# MK50D10 register map
Vendor: Freescale Semiconductor, Inc.; Series: Kinetis_K; File version: 1.6
CPU: CM4 r0p1, little endian, no MPU, no FPU, VTOR, 4 interrupt priority bits
Registers are 8-bit, read-write, reset 0x0 unless marked. A register's access mark holds for its fields unless they carry their own. Offsets are from the block's base; [hi:lo] are bit positions; {n}, {i} and the like mark numbered series; 'fields as' and 'values as' point back to an identical list.

## MPU — Memory protection unit
Base 0x4000D000; register names take the prefix MPU_
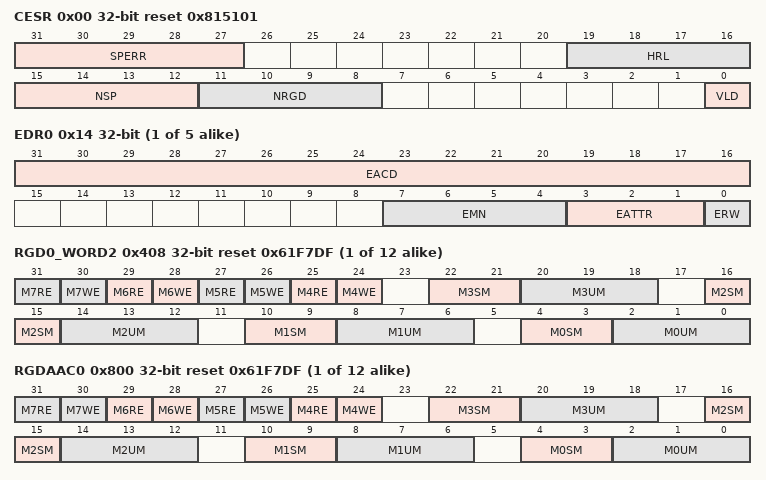
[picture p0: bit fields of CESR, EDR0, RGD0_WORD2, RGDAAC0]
0x00 CESR 32-bit reset 0x815101 — Control/Error Status Register
  [31:27] SPERR — Slave Port n Error
    0=No error has occurred for slave port n; 1=An error has occurred for slave port n
  [19:16] HRL ro — Hardware Revision Level
  [15:12] NSP ro — Number Of Slave Ports
  [11:8] NRGD ro — Number Of Region Descriptors
    0=8 region descriptors; 1=12 region descriptors; 2=16 region descriptors
  [0] VLD — Valid
    0=MPU is disabled. All accesses from all bus masters are allowed.; 1=MPU is enabled
{0x10+8i} EAR{i} (i=0..4) 32-bit ro reset not defined — Error Address Register, slave port n
  [31:0] EADDR — Error Address
{0x14+8i} EDR{i} (i=0..4) 32-bit ro reset not defined — Error Detail Register, slave port n
  [31:16] EACD — Error Access Control Detail
  [7:4] EMN — Error Master Number
  [3:1] EATTR — Error Attributes
    0=User mode, instruction access; 1=User mode, data access; 2=Supervisor mode, instruction access; 3=Supervisor mode, data access
  [0] ERW — Error Read/Write
    0=Read; 1=Write
{0x400+0x10*i} RGD{i}_WORD0 (i=0..11) 32-bit — Region Descriptor n, Word 0
  [31:5] SRTADDR — Start Address
{0x404+0x10*i} RGD{i}_WORD1 (i=0..11) 32-bit reset 0xFFFFFFFF — Region Descriptor n, Word 1
  [31:5] ENDADDR — End Address
{0x408+0x10*i} RGD{i}_WORD2 (i=0..11) 32-bit reset 0x61F7DF — Region Descriptor n, Word 2
  [2n+17] M{n}RE (n=4..7) — Bus Master {n} Read Enable
    0=Bus master {n} reads terminate with an access error and the read is not performed; 1=Bus master {n} reads allowed
  [2n+16] M{n}WE (n=4..7) — Bus Master {n} Write Enable
    0=Bus master {n} writes terminate with an access error and the write is not performed; 1=Bus master {n} writes allowed
  [22:21] M3SM — Bus Master 3 Supervisor Mode Access Control
    0=r/w/x; read, write and execute allowed; 1=r/x; read and execute allowed, but no write; 2=r/w; read and write allowed, but no execute; 3=Same as User mode defined in M3UM
  [20:18] M3UM — Bus Master 3 User Mode Access Control
    0=An attempted access of that mode may be terminated with an access error (if not allowed by another descriptor) and the access not performed; 1=Allows the given access type to occur
  [16:15] M2SM — Bus Master 2 Supervisor Mode Access Control
  [14:12] M2UM — Bus Master 2 User Mode Access control
  [10:9] M1SM — Bus Master 1 Supervisor Mode Access Control
  [8:6] M1UM — Bus Master 1 User Mode Access Control
  [4:3] M0SM — Bus Master 0 Supervisor Mode Access Control
  [2:0] M0UM — Bus Master 0 User Mode Access Control
{0x40C+0x10*i} RGD{i}_WORD3 (i=0..11) 32-bit reset 0x1 — Region Descriptor n, Word 3
  [0] VLD — Valid
    0=Region descriptor is invalid; 1=Region descriptor is valid
{0x800+4i} RGDAAC{i} (i=0..11) 32-bit reset 0x61F7DF — Region Descriptor Alternate Access Control n
  [2n+17] M{n}RE (n=4..7) — Bus Master {n} Read Enable
    values as RGD0_WORD2.M4RE
  [2n+16] M{n}WE (n=4..7) — Bus Master {n} Write Enable
    values as RGD0_WORD2.M4WE
  [22:21] M3SM — Bus Master 3 Supervisor Mode Access Control
    values as RGD0_WORD2.M3SM
  [20:18] M3UM — Bus Master 3 User Mode Access Control
    values as RGD0_WORD2.M3UM
  [16:15] M2SM — Bus Master 2 Supervisor Mode Access Control
  [14:12] M2UM — Bus Master 2 User Mode Access Control
  [10:9] M1SM — Bus Master 1 Supervisor Mode Access Control
  [8:6] M1UM — Bus Master 1 User Mode Access Control
  [4:3] M0SM — Bus Master 0 Supervisor Mode Access Control
  [2:0] M0UM — Bus Master 0 User Mode Access Control

## FTFL — Flash Memory Interface
Base 0x40020000; register names take the prefix FTFL_
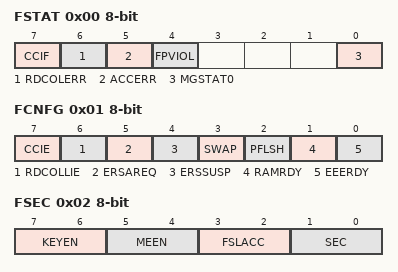
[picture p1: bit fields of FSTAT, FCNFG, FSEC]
0x00 FSTAT — Flash Status Register
  [7] CCIF — Command Complete Interrupt Flag
    0=Flash command in progress; 1=Flash command has completed
  [6] RDCOLERR — Flash Read Collision Error Flag
    0=No collision error detected; 1=Collision error detected
  [5] ACCERR — Flash Access Error Flag
    0=No access error detected; 1=Access error detected
  [4] FPVIOL — Flash Protection Violation Flag
    0=No protection violation detected; 1=Protection violation detected
  [0] MGSTAT0 ro — Memory Controller Command Completion Status Flag
0x01 FCNFG — Flash Configuration Register
  [7] CCIE — Command Complete Interrupt Enable
    0=Command complete interrupt disabled; 1=Command complete interrupt enabled. An interrupt request is generated whenever the FSTAT[CCIF] flag is set.
  [6] RDCOLLIE — Read Collision Error Interrupt Enable
    0=Read collision error interrupt disabled; 1=Read collision error interrupt enabled. An interrupt request is generated whenever a flash memory read collision error is detected (see the description of FSTAT[RDCOLERR]).
  [5] ERSAREQ ro — Erase All Request
    0=No request or request complete; 1=Request to: run the Erase All Blocks command, verify the erased state, program the security byte in the Flash Configuration Field to the unsecure state, and release MCU security by setting the FSEC[SEC] field to the unsecure state
  [4] ERSSUSP — Erase Suspend
    0=No suspend requested; 1=Suspend the current Erase Flash Sector command execution
  [3] SWAP ro
    0=Physical program flash 0 is located at relative address 0x0000; 1=If the PFLSH flag is set, physical program flash 1 is located at relative address 0x0000. If the PFLSH flag is not set, physical program flash 0 is located at relative address 0x0000
  [2] PFLSH ro — Flash memory configuration
    1=Flash memory module configured for program flash only, without support for data flash and/or EEPROM
  [1] RAMRDY ro — RAM Ready
    0=Programming acceleration RAM is not available; 1=Programming acceleration RAM is available
  [0] EEERDY ro — This field is reserved.
0x02 FSEC ro reset not defined — Flash Security Register
  [7:6] KEYEN — Backdoor Key Security Enable
    0=Backdoor key access disabled; 1=Backdoor key access disabled (preferred KEYEN state to disable backdoor key access); 2=Backdoor key access enabled; 3=Backdoor key access disabled
  [5:4] MEEN — Mass Erase Enable Bits
    0=Mass erase is enabled; 1=Mass erase is enabled; 2=Mass erase is disabled; 3=Mass erase is enabled
  [3:2] FSLACC — Freescale Failure Analysis Access Code
    0=Freescale factory access granted; 1=Freescale factory access denied; 2=Freescale factory access denied; 3=Freescale factory access granted
  [1:0] SEC — Flash Security
    0=MCU security status is secure; 1=MCU security status is secure; 2=MCU security status is unsecure (The standard shipping condition of the flash memory module is unsecure.); 3=MCU security status is secure
0x03 FOPT ro reset not defined — Flash Option Register
  [7:0] OPT — Nonvolatile Option
0x04 FCCOB{x} (x=3,2,1,0,7,6,5,4,B,A,9,8; step 0x1) — Flash Common Command Object Registers
  [7:0] CCOBn — The FCCOB register provides a command code and relevant parameters to the memory controller
0x10 FPROT{x} (x=3,2,1,0; step 0x1) reset not defined — Program Flash Protection Registers
  [7:0] PROT — Program Flash Region Protect
    0=Program flash region is protected; 1=Program flash region is not protected
